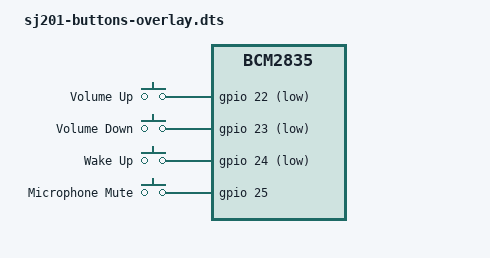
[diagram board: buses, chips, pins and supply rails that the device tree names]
/*
 * Device Tree Overlay for SJ-201 Rev6&10 - GPIO buttons.
 *
 * Exposes the four front-panel GPIO buttons as a gpio-keys input device:
 *   GPIO 22 = Volume Up    (KEY_VOLUMEUP)
 *   GPIO 23 = Volume Down  (KEY_VOLUMEDOWN)
 *   GPIO 24 = Wake/Action  (KEY_VOICECOMMAND, wakeup-capable)
 *   GPIO 25 = Mic Mute     (KEY_MICMUTE)
 *
 * Source: OpenVoiceOS/VocalFusionDriver (MIT). Compiled to
 * sj201-buttons-overlay.dtbo by the sj201-dtoverlays recipe.
 */

/dts-v1/;
/plugin/;

/ {
    compatible = "brcm,bcm2835";

    fragment@0 {
        target = <&gpio>;
        __overlay__ {
            sj201_key_pins: sj201_key_pins {
                brcm,pins = <22 23 24 25>;
                brcm,function = <0>; /* input */
                brcm,pull = <0>;     /* no pull */
            };
        };
    };

    fragment@1 {
        target-path = "/soc";
        __overlay__ {
            sj201_buttons: sj201_buttons {
                compatible = "gpio-keys";
                pinctrl-names = "default";
                pinctrl-0 = <&sj201_key_pins>;
                status = "okay";
                debounce-interval = <50>;

                button_volume_up: button@22 {
                    gpios = <&gpio 22 1>;
                    linux,code = <115>; /* KEY_VOLUMEUP */
                    label = "Volume Up";
                };

                button_volume_down: button@23 {
                    gpios = <&gpio 23 1>;
                    linux,code = <114>; /* KEY_VOLUMEDOWN */
                    label = "Volume Down";
                };

                button_wake_up: button@24 {
                    gpios = <&gpio 24 1>;
                    linux,code = <582>; /* KEY_VOICECOMMAND */
                    label = "Wake Up";
                    gpio-key,wakeup;
                };

                switch_mic_mute: button@25 {
                    gpios = <&gpio 25 0>;
                    linux,code = <248>; /* KEY_MICMUTE */
                    label = "Microphone Mute";
                };
            };
        };
    };
};
